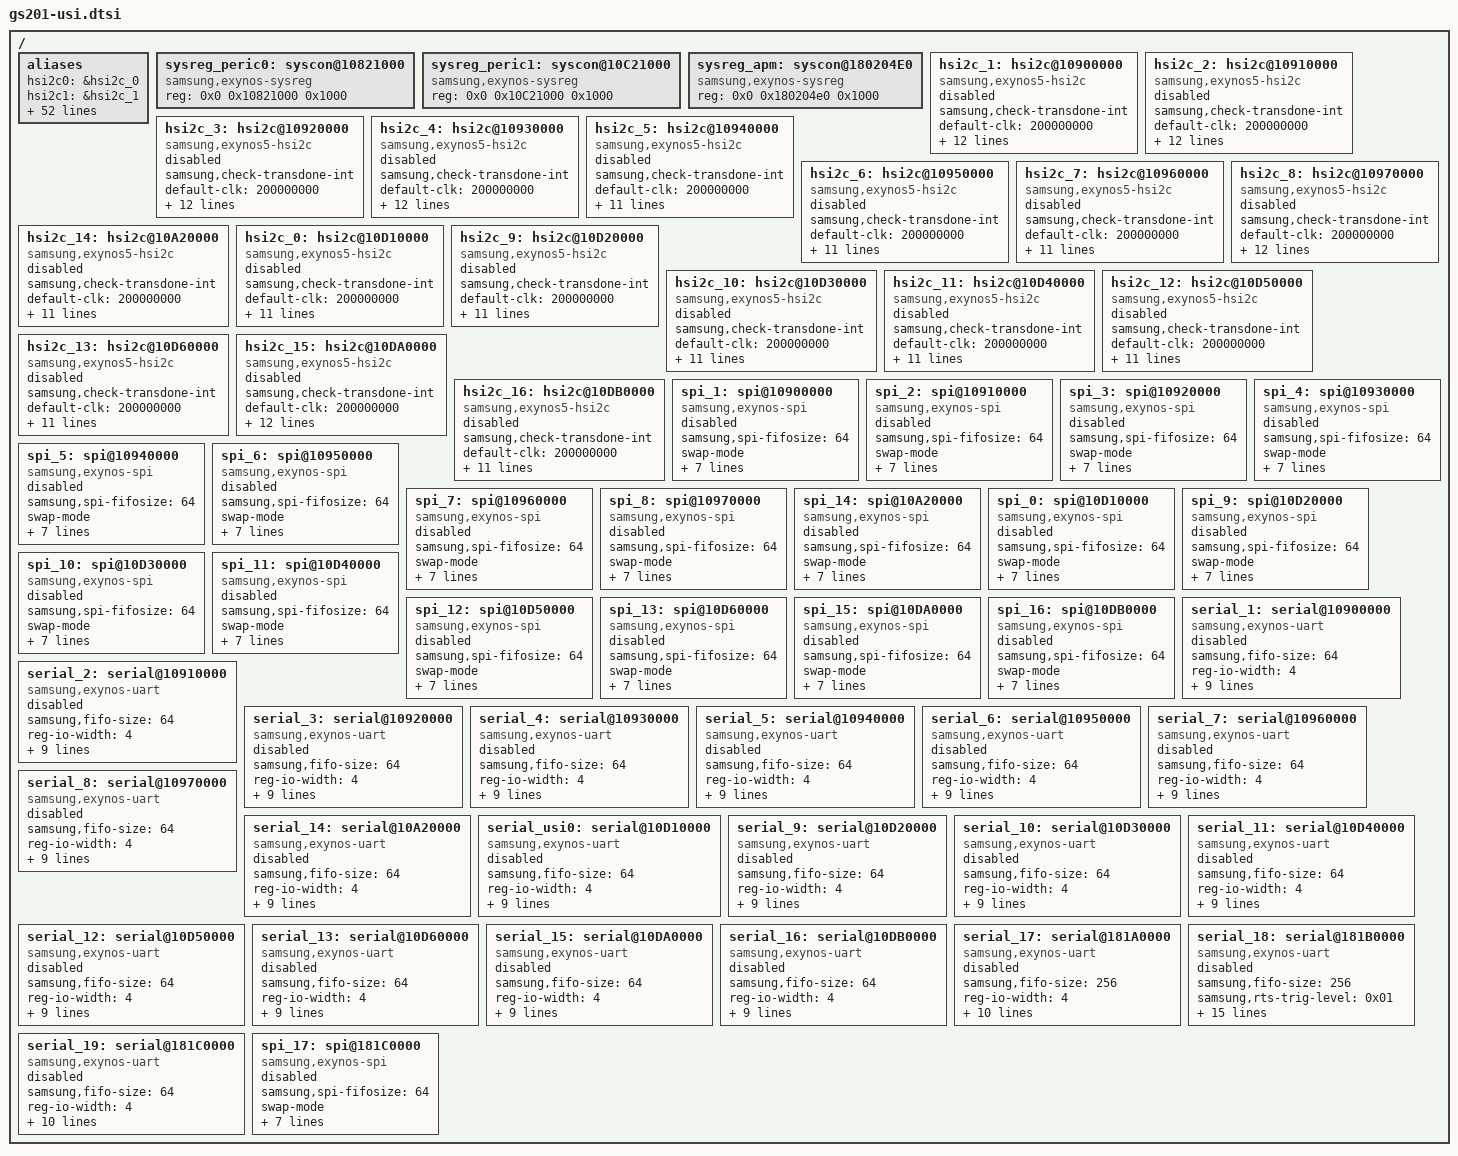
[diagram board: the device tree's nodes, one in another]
// SPDX-License-Identifier: GPL-2.0-only
/*
 * Copyright 2020 Google LLC.
 *
 */

/ {
	aliases {
		hsi2c0 = &hsi2c_0;
		hsi2c1 = &hsi2c_1;
		hsi2c2 = &hsi2c_2;
		hsi2c3 = &hsi2c_3;
		hsi2c4 = &hsi2c_4;
		hsi2c5 = &hsi2c_5;
		hsi2c6 = &hsi2c_6;
		hsi2c7 = &hsi2c_7;
		hsi2c8 = &hsi2c_8;
		hsi2c9 = &hsi2c_9;
		hsi2c10 = &hsi2c_10;
		hsi2c11 = &hsi2c_11;
		hsi2c12 = &hsi2c_12;
		hsi2c13 = &hsi2c_13;
		hsi2c14 = &hsi2c_14;
		hsi2c15 = &hsi2c_15;
		hsi2c16 = &hsi2c_16;
		spi0 = &spi_0;
		spi1 = &spi_1;
		spi2 = &spi_2;
		spi3 = &spi_3;
		spi4 = &spi_4;
		spi5 = &spi_5;
		spi6 = &spi_6;
		spi7 = &spi_7;
		spi8 = &spi_8;
		spi9 = &spi_9;
		spi10 = &spi_10;
		spi11 = &spi_11;
		spi12 = &spi_12;
		spi13 = &spi_13;
		spi14 = &spi_14;
		spi15 = &spi_15;
		spi16 = &spi_16;
		spi17 = &spi_17;
		uart1 = &serial_1;
		uart2 = &serial_2;
		uart3 = &serial_3;
		uart4 = &serial_4;
		uart5 = &serial_5;
		uart6 = &serial_6;
		uart7 = &serial_7;
		uart8 = &serial_8;
		uart9 = &serial_9;
		uart10 = &serial_10;
		uart11 = &serial_11;
		uart12 = &serial_12;
		uart13 = &serial_13;
		uart14 = &serial_14;
		uart15 = &serial_15;
		uart16 = &serial_16;
		uart17 = &serial_17;
		uart18 = &serial_18;
		uart19 = &serial_19;
	};

	sysreg_peric0: syscon@10821000 {
		compatible = "samsung,exynos-sysreg", "syscon";
		reg = <0x0 0x10821000 0x1000>;
	};

	sysreg_peric1: syscon@10C21000 {
		compatible = "samsung,exynos-sysreg", "syscon";
		reg = <0x0 0x10C21000 0x1000>;
	};

	sysreg_apm: syscon@180204E0 {
		compatible = "samsung,exynos-sysreg", "syscon";
		reg = <0x0 0x180204e0 0x1000>;
	};

	hsi2c_1: hsi2c@10900000 {
		compatible = "samsung,exynos5-hsi2c";
		samsung,check-transdone-int;
		#address-cells = <0x00000001>;
		#size-cells = <0x00000000>;
		default-clk = <200000000>;
		samsung,scl-clk-stretching;
		samsung,no_lose_arbitration;
		samsung,usi-i2c-v2;
		interrupts = <GIC_SPI IRQ_USI1_USI_PERIC0 ITLH>;
		samsung,usi-phandle = <&sysreg_peric0>;
		pinctrl-names = "default";
		pinctrl-0 = <&hsi2c1_bus>;
		clocks = <&clock VDOUT_CLK_PERIC0_USI1_USI>, <&clock GATE_PERIC0_TOP0_USI1_USI>;
		clock-names = "ipclk_hsi2c", "gate_hsi2c_clk";
		gpio_scl= <&gpp2 0 0x1>;
		gpio_sda= <&gpp2 1 0x1>;
		samsung,usi-offset = <0x00000000>;
		reg = <0x00000000 0x10900000 0x00001000>;
		status = "disabled";
	};
	hsi2c_2: hsi2c@10910000 {
		compatible = "samsung,exynos5-hsi2c";
		samsung,check-transdone-int;
		#address-cells = <0x00000001>;
		#size-cells = <0x00000000>;
		default-clk = <200000000>;
		samsung,scl-clk-stretching;
		samsung,no_lose_arbitration;
		samsung,usi-i2c-v2;
		interrupts = <GIC_SPI IRQ_USI2_USI_PERIC0 ITLH>;
		pinctrl-names = "default";
		pinctrl-0 = <&hsi2c2_bus>;
		clocks = <&clock VDOUT_CLK_PERIC0_USI2_USI>, <&clock GATE_PERIC0_TOP0_USI2_USI>;
		clock-names = "ipclk_hsi2c", "gate_hsi2c_clk";
		gpio_scl= <&gpp4 0 0x1>;
		gpio_sda= <&gpp4 1 0x1>;
		samsung,usi-phandle = <&sysreg_peric0>;
		samsung,usi-offset = <0x00000004>;
		reg = <0x00000000 0x10910000 0x00001000>;
		status = "disabled";
	};
	hsi2c_3: hsi2c@10920000 {
		compatible = "samsung,exynos5-hsi2c";
		samsung,check-transdone-int;
		#address-cells = <0x00000001>;
		#size-cells = <0x00000000>;
		default-clk = <200000000>;
		samsung,scl-clk-stretching;
		samsung,no_lose_arbitration;
		samsung,usi-i2c-v2;
		interrupts = <GIC_SPI IRQ_USI3_USI_PERIC0 ITLH>;
		pinctrl-names = "default";
		pinctrl-0 = <&hsi2c3_bus>;
		clocks = <&clock VDOUT_CLK_PERIC0_USI3_USI>, <&clock GATE_PERIC0_TOP0_USI3_USI>;
		clock-names = "ipclk_hsi2c", "gate_hsi2c_clk";
		gpio_scl= <&gpp6 0 0x1>;
		gpio_sda= <&gpp6 1 0x1>;
		samsung,usi-phandle = <&sysreg_peric0>;
		samsung,usi-offset = <0x00000008>;
		reg = <0x00000000 0x10920000 0x00001000>;
		status = "disabled";
	};
	hsi2c_4: hsi2c@10930000 {
		compatible = "samsung,exynos5-hsi2c";
		samsung,check-transdone-int;
		#address-cells = <0x00000001>;
		#size-cells = <0x00000000>;
		default-clk = <200000000>;
		samsung,scl-clk-stretching;
		samsung,no_lose_arbitration;
		samsung,usi-i2c-v2;
		interrupts = <GIC_SPI IRQ_USI4_USI_PERIC0 ITLH>;
		pinctrl-names = "default";
		pinctrl-0 = <&hsi2c4_bus>;
		clocks = <&clock VDOUT_CLK_PERIC0_USI4_USI>, <&clock GATE_PERIC0_TOP0_USI4_USI>;
		clock-names = "ipclk_hsi2c", "gate_hsi2c_clk";
		gpio_scl= <&gpp8 0 0x1>;
		gpio_sda= <&gpp8 1 0x1>;
		samsung,usi-phandle = <&sysreg_peric0>;
		samsung,usi-offset = <0x0000000c>;
		reg = <0x00000000 0x10930000 0x00001000>;
		status = "disabled";
	};
	hsi2c_5: hsi2c@10940000 {
		compatible = "samsung,exynos5-hsi2c";
		samsung,check-transdone-int;
		#address-cells = <0x00000001>;
		#size-cells = <0x00000000>;
		default-clk = <200000000>;
		samsung,scl-clk-stretching;
		samsung,usi-i2c-v2;
		interrupts = <GIC_SPI IRQ_USI5_USI_PERIC0 ITLH>;
		pinctrl-names = "default";
		pinctrl-0 = <&hsi2c5_bus>;
		clocks = <&clock VDOUT_CLK_PERIC0_USI5_USI>, <&clock GATE_PERIC0_TOP0_USI5_USI>;
		clock-names = "ipclk_hsi2c", "gate_hsi2c_clk";
		gpio_scl= <&gpp10 0 0x1>;
		gpio_sda= <&gpp10 1 0x1>;
		samsung,usi-phandle = <&sysreg_peric0>;
		samsung,usi-offset = <0x00000010>;
		reg = <0x00000000 0x10940000 0x00001000>;
		status = "disabled";
	};
	hsi2c_6: hsi2c@10950000 {
		compatible = "samsung,exynos5-hsi2c";
		samsung,check-transdone-int;
		#address-cells = <0x00000001>;
		#size-cells = <0x00000000>;
		default-clk = <200000000>;
		samsung,scl-clk-stretching;
		samsung,usi-i2c-v2;
		interrupts = <GIC_SPI IRQ_USI6_USI_PERIC0 ITLH>;
		pinctrl-names = "default";
		pinctrl-0 = <&hsi2c6_bus>;
		clocks = <&clock VDOUT_CLK_PERIC0_USI6_USI>, <&clock GATE_PERIC0_TOP0_USI6_USI>;
		clock-names = "ipclk_hsi2c", "gate_hsi2c_clk";
		gpio_scl= <&gpp12 0 0x1>;
		gpio_sda= <&gpp12 1 0x1>;
		samsung,usi-phandle = <&sysreg_peric0>;
		samsung,usi-offset = <0x00000014>;
		reg = <0x00000000 0x10950000 0x00001000>;
		status = "disabled";
	};
	hsi2c_7: hsi2c@10960000 {
		compatible = "samsung,exynos5-hsi2c";
		samsung,check-transdone-int;
		#address-cells = <0x00000001>;
		#size-cells = <0x00000000>;
		default-clk = <200000000>;
		samsung,scl-clk-stretching;
		samsung,usi-i2c-v2;
		interrupts = <GIC_SPI IRQ_USI7_USI_PERIC0 ITLH>;
		pinctrl-names = "default";
		pinctrl-0 = <&hsi2c7_bus>;
		clocks = <&clock VDOUT_CLK_PERIC0_USI7_USI>, <&clock GATE_PERIC0_TOP0_USI7_USI>;
		clock-names = "ipclk_hsi2c", "gate_hsi2c_clk";
		gpio_scl= <&gpp14 0 0x1>;
		gpio_sda= <&gpp14 1 0x1>;
		samsung,usi-phandle = <&sysreg_peric0>;
		samsung,usi-offset = <0x00000018>;
		reg = <0x00000000 0x10960000 0x00001000>;
		status = "disabled";
	};
	hsi2c_8: hsi2c@10970000 {
		compatible = "samsung,exynos5-hsi2c";
		samsung,check-transdone-int;
		#address-cells = <0x00000001>;
		#size-cells = <0x00000000>;
		default-clk = <200000000>;
		samsung,scl-clk-stretching;
		samsung,no_lose_arbitration;
		samsung,usi-i2c-v2;
		interrupts = <GIC_SPI IRQ_USI8_USI_PERIC0 ITLH>;
		pinctrl-names = "default";
		pinctrl-0 = <&hsi2c8_bus>;
		clocks = <&clock VDOUT_CLK_PERIC0_USI8_USI>, <&clock GATE_PERIC0_TOP0_USI8_USI>;
		clock-names = "ipclk_hsi2c", "gate_hsi2c_clk";
		gpio_scl= <&gpp16 0 0x1>;
		gpio_sda= <&gpp16 1 0x1>;
		samsung,usi-phandle = <&sysreg_peric0>;
		samsung,usi-offset = <0x0000001c>;
		reg = <0x00000000 0x10970000 0x00001000>;
		status = "disabled";
	};
	hsi2c_14: hsi2c@10A20000 {
		compatible = "samsung,exynos5-hsi2c";
		samsung,check-transdone-int;
		#address-cells = <0x00000001>;
		#size-cells = <0x00000000>;
		default-clk = <200000000>;
		samsung,scl-clk-stretching;
		samsung,usi-i2c-v2;
		interrupts = <GIC_SPI IRQ_USI14_USI_PERIC0 ITLH>;
		pinctrl-names = "default";
		pinctrl-0 = <&hsi2c14_bus>;
		clocks = <&clock VDOUT_CLK_PERIC0_USI14_USI>, <&clock GATE_PERIC0_TOP1_USI14_USI>;
		clock-names = "ipclk_hsi2c", "gate_hsi2c_clk";
		gpio_scl= <&gpp18 0 0x1>;
		gpio_sda= <&gpp18 1 0x1>;
		samsung,usi-phandle = <&sysreg_peric0>;
		samsung,usi-offset = <0x00000028>;
		reg = <0x00000000 0x10a20000 0x00001000>;
		status = "disabled";
	};
	hsi2c_0: hsi2c@10D10000 {
		compatible = "samsung,exynos5-hsi2c";
		samsung,check-transdone-int;
		#address-cells = <0x00000001>;
		#size-cells = <0x00000000>;
		default-clk = <200000000>;
		samsung,scl-clk-stretching;
		samsung,usi-i2c-v2;
		interrupts = <GIC_SPI IRQ_USI0_USI_PERIC1 ITLH>;
		pinctrl-names = "default";
		pinctrl-0 = <&hsi2c0_bus>;
		clocks = <&clock VDOUT_CLK_PERIC1_USI0_USI>, <&clock GATE_PERIC1_TOP0_USI0_USI>;
		clock-names = "ipclk_hsi2c", "gate_hsi2c_clk";
		gpio_scl= <&gpp20 0 0x1>;
		gpio_sda= <&gpp20 1 0x1>;
		samsung,usi-phandle = <&sysreg_peric1>;
		samsung,usi-offset = <0x00000000>;
		reg = <0x00000000 0x10d10000 0x00001000>;
		status = "disabled";
	};
	hsi2c_9: hsi2c@10D20000 {
		compatible = "samsung,exynos5-hsi2c";
		samsung,check-transdone-int;
		#address-cells = <0x00000001>;
		#size-cells = <0x00000000>;
		default-clk = <200000000>;
		samsung,scl-clk-stretching;
		samsung,usi-i2c-v2;
		interrupts = <GIC_SPI IRQ_USI9_USI_PERIC1 ITLH>;
		pinctrl-names = "default";
		pinctrl-0 = <&hsi2c9_bus>;
		clocks = <&clock VDOUT_CLK_PERIC1_USI9_USI>, <&clock GATE_PERIC1_TOP0_USI9_USI>;
		clock-names = "ipclk_hsi2c", "gate_hsi2c_clk";
		gpio_scl= <&gpp20 4 0x1>;
		gpio_sda= <&gpp20 5 0x1>;
		samsung,usi-phandle = <&sysreg_peric1>;
		samsung,usi-offset = <0x00000004>;
		reg = <0x00000000 0x10d20000 0x00001000>;
		status = "disabled";
	};
	hsi2c_10: hsi2c@10D30000 {
		compatible = "samsung,exynos5-hsi2c";
		samsung,check-transdone-int;
		#address-cells = <0x00000001>;
		#size-cells = <0x00000000>;
		default-clk = <200000000>;
		samsung,scl-clk-stretching;
		samsung,usi-i2c-v2;
		interrupts = <GIC_SPI IRQ_USI10_USI_PERIC1 ITLH>;
		pinctrl-names = "default";
		pinctrl-0 = <&hsi2c10_bus>;
		clocks = <&clock VDOUT_CLK_PERIC1_USI10_USI>, <&clock GATE_PERIC1_TOP0_USI10_USI>;
		clock-names = "ipclk_hsi2c", "gate_hsi2c_clk";
		gpio_scl= <&gpp21 0 0x1>;
		gpio_sda= <&gpp21 1 0x1>;
		samsung,usi-phandle = <&sysreg_peric1>;
		samsung,usi-offset = <0x00000008>;
		reg = <0x00000000 0x10d30000 0x00001000>;
		status = "disabled";
	};
	hsi2c_11: hsi2c@10D40000 {
		compatible = "samsung,exynos5-hsi2c";
		samsung,check-transdone-int;
		#address-cells = <0x00000001>;
		#size-cells = <0x00000000>;
		default-clk = <200000000>;
		samsung,scl-clk-stretching;
		samsung,usi-i2c-v2;
		interrupts = <GIC_SPI IRQ_USI11_USI_PERIC1 ITLH>;
		pinctrl-names = "default";
		pinctrl-0 = <&hsi2c11_bus>;
		clocks = <&clock VDOUT_CLK_PERIC1_USI11_USI>, <&clock GATE_PERIC1_TOP0_USI11_USI>;
		clock-names = "ipclk_hsi2c", "gate_hsi2c_clk";
		gpio_scl= <&gpp23 0 0x1>;
		gpio_sda= <&gpp23 1 0x1>;
		samsung,usi-phandle = <&sysreg_peric1>;
		samsung,usi-offset = <0x0000000c>;
		reg = <0x00000000 0x10d40000 0x00001000>;
		status = "disabled";
	};
	hsi2c_12: hsi2c@10D50000 {
		compatible = "samsung,exynos5-hsi2c";
		samsung,check-transdone-int;
		#address-cells = <0x00000001>;
		#size-cells = <0x00000000>;
		default-clk = <200000000>;
		samsung,scl-clk-stretching;
		samsung,usi-i2c-v2;
		interrupts = <GIC_SPI IRQ_USI12_USI_PERIC1 ITLH>;
		pinctrl-names = "default";
		pinctrl-0 = <&hsi2c12_bus>;
		clocks = <&clock VDOUT_CLK_PERIC1_USI12_USI>, <&clock GATE_PERIC1_TOP0_USI12_USI>;
		clock-names = "ipclk_hsi2c", "gate_hsi2c_clk";
		gpio_scl= <&gpp23 4 0x1>;
		gpio_sda= <&gpp23 5 0x1>;
		samsung,usi-phandle = <&sysreg_peric1>;
		samsung,usi-offset = <0x00000010>;
		reg = <0x00000000 0x10d50000 0x00001000>;
		status = "disabled";
	};
	hsi2c_13: hsi2c@10D60000 {
		compatible = "samsung,exynos5-hsi2c";
		samsung,check-transdone-int;
		#address-cells = <0x00000001>;
		#size-cells = <0x00000000>;
		default-clk = <200000000>;
		samsung,scl-clk-stretching;
		samsung,usi-i2c-v2;
		interrupts = <GIC_SPI IRQ_USI13_USI_PERIC1 ITLH>;
		pinctrl-names = "default";
		pinctrl-0 = <&hsi2c13_bus>;
		clocks = <&clock VDOUT_CLK_PERIC1_USI13_USI>, <&clock GATE_PERIC1_TOP0_USI13_USI>;
		clock-names = "ipclk_hsi2c", "gate_hsi2c_clk";
		gpio_scl= <&gpp25 0 0x1>;
		gpio_sda= <&gpp25 1 0x1>;
		samsung,usi-phandle = <&sysreg_peric1>;
		samsung,usi-offset = <0x00000014>;
		reg = <0x00000000 0x10d60000 0x00001000>;
		status = "disabled";
	};
	hsi2c_15: hsi2c@10DA0000 {
		compatible = "samsung,exynos5-hsi2c";
		samsung,check-transdone-int;
		#address-cells = <0x00000001>;
		#size-cells = <0x00000000>;
		default-clk = <200000000>;
		samsung,scl-clk-stretching;
		samsung,no_lose_arbitration;
		samsung,usi-i2c-v2;
		interrupts = <GIC_SPI IRQ_USI15_USI_PERIC1 ITLH>;
		pinctrl-names = "default";
		pinctrl-0 = <&hsi2c15_bus>;
		clocks = <&clock VDOUT_CLK_PERIC1_USI15_USI>, <&clock GATE_PERIC1_TOP0_USI15_USI>;
		clock-names = "ipclk_hsi2c", "gate_hsi2c_clk";
		gpio_scl= <&gpp24 0 0x1>;
		gpio_sda= <&gpp24 1 0x1>;
		samsung,usi-phandle = <&sysreg_peric1>;
		samsung,usi-offset = <0x00000018>;
		reg = <0x00000000 0x10da0000 0x00001000>;
		status = "disabled";
	};
	hsi2c_16: hsi2c@10DB0000 {
		compatible = "samsung,exynos5-hsi2c";
		samsung,check-transdone-int;
		#address-cells = <0x00000001>;
		#size-cells = <0x00000000>;
		default-clk = <200000000>;
		samsung,scl-clk-stretching;
		samsung,usi-i2c-v2;
		interrupts = <GIC_SPI IRQ_USI16_USI_PERIC1 ITLH>;
		pinctrl-names = "default";
		pinctrl-0 = <&hsi2c16_bus>;
		clocks = <&clock VDOUT_CLK_PERIC1_USI16_USI>, <&clock GATE_PERIC1_TOP0_USI16_USI>;
		clock-names = "ipclk_hsi2c", "gate_hsi2c_clk";
		gpio_scl= <&gpp26 0 0x1>;
		gpio_sda= <&gpp26 1 0x1>;
		samsung,usi-phandle = <&sysreg_peric1>;
		samsung,usi-offset = <0x0000001c>;
		reg = <0x00000000 0x10db0000 0x00001000>;
		status = "disabled";
	};
	spi_1: spi@10900000 {
		compatible = "samsung,exynos-spi";
		samsung,spi-fifosize = <64>;
		swap-mode;
		#address-cells = <0x00000001>;
		#size-cells = <0x00000000>;
//		dma-mode;
//		dmas = <&pdma0 2 &pdma0 3>;
		dma-names = "tx", "rx";
		clocks = <&clock VDOUT_CLK_PERIC0_USI1_USI>, <&clock GATE_PERIC0_TOP0_USI1_USI>;
		clock-names = "ipclk_spi", "gate_spi_clk";
		pinctrl-names = "default";
		pinctrl-0 = <&spi1_bus>;
		interrupts = <GIC_SPI IRQ_USI1_USI_PERIC0 ITLH>;
		samsung,usi-phandle = <&sysreg_peric0>;
		samsung,usi-offset = <0x00000000>;
		reg = <0x00000000 0x10900000 0x00001000>;
		status = "disabled";
	};
	spi_2: spi@10910000 {
		compatible = "samsung,exynos-spi";
		samsung,spi-fifosize = <64>;
		swap-mode;
		#address-cells = <0x00000001>;
		#size-cells = <0x00000000>;
//		dma-mode;
//		dmas = <&pdma0 4 &pdma0 5>;
		dma-names = "tx", "rx";
		clocks = <&clock VDOUT_CLK_PERIC0_USI2_USI>, <&clock GATE_PERIC0_TOP0_USI2_USI>;
		clock-names = "ipclk_spi", "gate_spi_clk";
		pinctrl-names = "default";
		pinctrl-0 = <&spi2_bus>;
		interrupts = <GIC_SPI IRQ_USI2_USI_PERIC0 ITLH>;
		samsung,usi-phandle = <&sysreg_peric0>;
		samsung,usi-offset = <0x00000004>;
		reg = <0x00000000 0x10910000 0x00001000>;
		status = "disabled";
	};
	spi_3: spi@10920000 {
		compatible = "samsung,exynos-spi";
		samsung,spi-fifosize = <64>;
		swap-mode;
		#address-cells = <0x00000001>;
		#size-cells = <0x00000000>;
//		dma-mode;
//		dmas = <&pdma0 6 &pdma0 7>;
		dma-names = "tx", "rx";
		clocks = <&clock VDOUT_CLK_PERIC0_USI3_USI>, <&clock GATE_PERIC0_TOP0_USI3_USI>;
		clock-names = "ipclk_spi", "gate_spi_clk";
		pinctrl-names = "default";
		pinctrl-0 = <&spi3_bus>;
		interrupts = <GIC_SPI IRQ_USI3_USI_PERIC0 ITLH>;
		samsung,usi-phandle = <&sysreg_peric0>;
		samsung,usi-offset = <0x00000008>;
		reg = <0x00000000 0x10920000 0x00001000>;
		status = "disabled";
	};
	spi_4: spi@10930000 {
		compatible = "samsung,exynos-spi";
		samsung,spi-fifosize = <64>;
		swap-mode;
		#address-cells = <0x00000001>;
		#size-cells = <0x00000000>;
//		dma-mode;
//		dmas = <&pdma0 8 &pdma0 9>;
		dma-names = "tx", "rx";
		clocks = <&clock VDOUT_CLK_PERIC0_USI4_USI>, <&clock GATE_PERIC0_TOP0_USI4_USI>;
		clock-names = "ipclk_spi", "gate_spi_clk";
		pinctrl-names = "default";
		pinctrl-0 = <&spi4_bus>;
		interrupts = <GIC_SPI IRQ_USI4_USI_PERIC0 ITLH>;
		samsung,usi-phandle = <&sysreg_peric0>;
		samsung,usi-offset = <0x0000000c>;
		reg = <0x00000000 0x10930000 0x00001000>;
		status = "disabled";
	};
	spi_5: spi@10940000 {
		compatible = "samsung,exynos-spi";
		samsung,spi-fifosize = <64>;
		swap-mode;
		#address-cells = <0x00000001>;
		#size-cells = <0x00000000>;
//		dma-mode;
//		dmas = <&pdma0 10 &pdma0 11>;
		dma-names = "tx", "rx";
		clocks = <&clock VDOUT_CLK_PERIC0_USI5_USI>, <&clock GATE_PERIC0_TOP0_USI5_USI>;
		clock-names = "ipclk_spi", "gate_spi_clk";
		pinctrl-names = "default";
		pinctrl-0 = <&spi5_bus>;
		interrupts = <GIC_SPI IRQ_USI5_USI_PERIC0 ITLH>;
		samsung,usi-phandle = <&sysreg_peric0>;
		samsung,usi-offset = <0x00000010>;
		reg = <0x00000000 0x10940000 0x00001000>;
		status = "disabled";
	};
	spi_6: spi@10950000 {
		compatible = "samsung,exynos-spi";
		samsung,spi-fifosize = <64>;
		swap-mode;
		#address-cells = <0x00000001>;
		#size-cells = <0x00000000>;
//		dma-mode;
//		dmas = <&pdma0 12 &pdma0 13>;
		dma-names = "tx", "rx";
		clocks = <&clock VDOUT_CLK_PERIC0_USI6_USI>, <&clock GATE_PERIC0_TOP0_USI6_USI>;
		clock-names = "ipclk_spi", "gate_spi_clk";
		pinctrl-names = "default";
		pinctrl-0 = <&spi6_bus>;
		interrupts = <GIC_SPI IRQ_USI6_USI_PERIC0 ITLH>;
		samsung,usi-phandle = <&sysreg_peric0>;
		samsung,usi-offset = <0x00000014>;
		reg = <0x00000000 0x10950000 0x00001000>;
		status = "disabled";
	};
	spi_7: spi@10960000 {
		compatible = "samsung,exynos-spi";
		samsung,spi-fifosize = <64>;
		swap-mode;
		#address-cells = <0x00000001>;
		#size-cells = <0x00000000>;
//		dma-mode;
//		dmas = <&pdma0 14 &pdma0 15>;
		dma-names = "tx", "rx";
		clocks = <&clock VDOUT_CLK_PERIC0_USI7_USI>, <&clock GATE_PERIC0_TOP0_USI7_USI>;
		clock-names = "ipclk_spi", "gate_spi_clk";
		pinctrl-names = "default";
		pinctrl-0 = <&spi7_bus>;
		interrupts = <GIC_SPI IRQ_USI7_USI_PERIC0 ITLH>;
		samsung,usi-phandle = <&sysreg_peric0>;
		samsung,usi-offset = <0x00000018>;
		reg = <0x00000000 0x10960000 0x00001000>;
		status = "disabled";
	};
	spi_8: spi@10970000 {
		compatible = "samsung,exynos-spi";
		samsung,spi-fifosize = <64>;
		swap-mode;
		#address-cells = <0x00000001>;
		#size-cells = <0x00000000>;
//		dma-mode;
//		dmas = <&pdma0 16 &pdma0 17>;
		dma-names = "tx", "rx";
		clocks = <&clock VDOUT_CLK_PERIC0_USI8_USI>, <&clock GATE_PERIC0_TOP0_USI8_USI>;
		clock-names = "ipclk_spi", "gate_spi_clk";
		pinctrl-names = "default";
		pinctrl-0 = <&spi8_bus>;
		interrupts = <GIC_SPI IRQ_USI8_USI_PERIC0 ITLH>;
		samsung,usi-phandle = <&sysreg_peric0>;
		samsung,usi-offset = <0x0000001c>;
		reg = <0x00000000 0x10970000 0x00001000>;
		status = "disabled";
	};
	spi_14: spi@10A20000 {
		compatible = "samsung,exynos-spi";
		samsung,spi-fifosize = <64>;
		swap-mode;
		#address-cells = <0x00000001>;
		#size-cells = <0x00000000>;
//		dma-mode;
//		dmas = <&pdma0 28 &pdma0 29>;
		dma-names = "tx", "rx";
		clocks = <&clock VDOUT_CLK_PERIC0_USI14_USI>, <&clock GATE_PERIC0_TOP1_USI14_USI>;
		clock-names = "ipclk_spi", "gate_spi_clk";
		pinctrl-names = "default";
		pinctrl-0 = <&spi14_bus>;
		interrupts = <GIC_SPI IRQ_USI14_USI_PERIC0 ITLH>;
		samsung,usi-phandle = <&sysreg_peric0>;
		samsung,usi-offset = <0x00000028>;
		reg = <0x00000000 0x10a20000 0x00001000>;
		status = "disabled";
	};
	spi_0: spi@10D10000 {
		compatible = "samsung,exynos-spi";
		samsung,spi-fifosize = <64>;
		swap-mode;
		#address-cells = <0x00000001>;
		#size-cells = <0x00000000>;
//		dma-mode;
//		dmas = <&pdma0 0 &pdma0 1>;
		dma-names = "tx", "rx";
		clocks = <&clock VDOUT_CLK_PERIC1_USI0_USI>, <&clock GATE_PERIC1_TOP0_USI0_USI>;
		clock-names = "ipclk_spi", "gate_spi_clk";
		pinctrl-names = "default";
		pinctrl-0 = <&spi0_bus>;
		interrupts = <GIC_SPI IRQ_USI0_USI_PERIC1 ITLH>;
		samsung,usi-phandle = <&sysreg_peric1>;
		samsung,usi-offset = <0x00000000>;
		reg = <0x00000000 0x10d10000 0x00001000>;
		status = "disabled";
	};
	spi_9: spi@10D20000 {
		compatible = "samsung,exynos-spi";
		samsung,spi-fifosize = <64>;
		swap-mode;
		#address-cells = <0x00000001>;
		#size-cells = <0x00000000>;
//		dma-mode;
//		dmas = <&pdma0 18 &pdma0 19>;
		dma-names = "tx", "rx";
		clocks = <&clock VDOUT_CLK_PERIC1_USI9_USI>, <&clock GATE_PERIC1_TOP0_USI9_USI>;
		clock-names = "ipclk_spi", "gate_spi_clk";
		pinctrl-names = "default";
		pinctrl-0 = <&spi9_bus>;
		interrupts = <GIC_SPI IRQ_USI9_USI_PERIC1 ITLH>;
		samsung,usi-phandle = <&sysreg_peric1>;
		samsung,usi-offset = <0x00000004>;
		reg = <0x00000000 0x10d20000 0x00001000>;
		status = "disabled";
	};
	spi_10: spi@10D30000 {
		compatible = "samsung,exynos-spi";
		samsung,spi-fifosize = <64>;
		swap-mode;
		#address-cells = <0x00000001>;
		#size-cells = <0x00000000>;
//		dma-mode;
//		dmas = <&pdma0 20 &pdma0 21>;
		dma-names = "tx", "rx";
		clocks = <&clock VDOUT_CLK_PERIC1_USI10_USI>, <&clock GATE_PERIC1_TOP0_USI10_USI>;
		clock-names = "ipclk_spi", "gate_spi_clk";
		pinctrl-names = "default";
		pinctrl-0 = <&spi10_bus>;
		interrupts = <GIC_SPI IRQ_USI10_USI_PERIC1 ITLH>;
		samsung,usi-phandle = <&sysreg_peric1>;
		samsung,usi-offset = <0x00000008>;
		reg = <0x00000000 0x10d30000 0x00001000>;
		status = "disabled";
	};
	spi_11: spi@10D40000 {
		compatible = "samsung,exynos-spi";
		samsung,spi-fifosize = <64>;
		swap-mode;
		#address-cells = <0x00000001>;
		#size-cells = <0x00000000>;
//		dma-mode;
//		dmas = <&pdma0 22 &pdma0 23>;
		dma-names = "tx", "rx";
		clocks = <&clock VDOUT_CLK_PERIC1_USI11_USI>, <&clock GATE_PERIC1_TOP0_USI11_USI>;
		clock-names = "ipclk_spi", "gate_spi_clk";
		pinctrl-names = "default";
		pinctrl-0 = <&spi11_bus>;
		interrupts = <GIC_SPI IRQ_USI11_USI_PERIC1 ITLH>;
		samsung,usi-phandle = <&sysreg_peric1>;
		samsung,usi-offset = <0x0000000c>;
		reg = <0x00000000 0x10d40000 0x00001000>;
		status = "disabled";
	};
	spi_12: spi@10D50000 {
		compatible = "samsung,exynos-spi";
		samsung,spi-fifosize = <64>;
		swap-mode;
		#address-cells = <0x00000001>;
		#size-cells = <0x00000000>;
//		dma-mode;
//		dmas = <&pdma0 24 &pdma0 25>;
		dma-names = "tx", "rx";
		clocks = <&clock VDOUT_CLK_PERIC1_USI12_USI>, <&clock GATE_PERIC1_TOP0_USI12_USI>;
		clock-names = "ipclk_spi", "gate_spi_clk";
		pinctrl-names = "default";
		pinctrl-0 = <&spi12_bus>;
		interrupts = <GIC_SPI IRQ_USI12_USI_PERIC1 ITLH>;
		samsung,usi-phandle = <&sysreg_peric1>;
		samsung,usi-offset = <0x00000010>;
		reg = <0x00000000 0x10d50000 0x00001000>;
		status = "disabled";
	};
	spi_13: spi@10D60000 {
		compatible = "samsung,exynos-spi";
		samsung,spi-fifosize = <64>;
		swap-mode;
		#address-cells = <0x00000001>;
		#size-cells = <0x00000000>;
//		dma-mode;
//		dmas = <&pdma1 0 &pdma1 1>;
		dma-names = "tx", "rx";
		clocks = <&clock VDOUT_CLK_PERIC1_USI13_USI>, <&clock GATE_PERIC1_TOP0_USI13_USI>;
		clock-names = "ipclk_spi", "gate_spi_clk";
		pinctrl-names = "default";
		pinctrl-0 = <&spi13_bus>;
		interrupts = <GIC_SPI IRQ_USI13_USI_PERIC1 ITLH>;
		samsung,usi-phandle = <&sysreg_peric1>;
		samsung,usi-offset = <0x00000014>;
		reg = <0x00000000 0x10d60000 0x00001000>;
		status = "disabled";
	};
	spi_15: spi@10DA0000 {
		compatible = "samsung,exynos-spi";
		samsung,spi-fifosize = <64>;
		swap-mode;
		#address-cells = <0x00000001>;
		#size-cells = <0x00000000>;
//		dma-mode;
//		dmas = <&pdma1 2 &pdma1 3>;
		dma-names = "tx", "rx";
		clocks = <&clock VDOUT_CLK_PERIC1_USI15_USI>, <&clock GATE_PERIC1_TOP0_USI15_USI>;
		clock-names = "ipclk_spi", "gate_spi_clk";
		pinctrl-names = "default";
		pinctrl-0 = <&spi15_bus>;
		interrupts = <GIC_SPI IRQ_USI15_USI_PERIC1 ITLH>;
		samsung,usi-phandle = <&sysreg_peric1>;
		samsung,usi-offset = <0x00000018>;
		reg = <0x00000000 0x10da0000 0x00001000>;
		status = "disabled";
	};
	spi_16: spi@10DB0000 {
		compatible = "samsung,exynos-spi";
		samsung,spi-fifosize = <64>;
		swap-mode;
		#address-cells = <0x00000001>;
		#size-cells = <0x00000000>;
//		dma-mode;
//		dmas = <&pdma0 26 &pdma0 27>;
		dma-names = "tx", "rx";
		clocks = <&clock VDOUT_CLK_PERIC1_USI16_USI>, <&clock GATE_PERIC1_TOP0_USI16_USI>;
		clock-names = "ipclk_spi", "gate_spi_clk";
		pinctrl-names = "default";
		pinctrl-0 = <&spi16_bus>;
		interrupts = <GIC_SPI IRQ_USI16_USI_PERIC1 ITLH>;
		samsung,usi-phandle = <&sysreg_peric1>;
		samsung,usi-offset = <0x0000001c>;
		reg = <0x00000000 0x10db0000 0x00001000>;
		status = "disabled";
	};
	/* BLK_PERIC0 USI1_USI */
	serial_1: serial@10900000 {
		compatible = "samsung,exynos-uart";
		samsung,fifo-size = <64>;
		reg-io-width = <4>;
		samsung,separate-uart-clk;
		samsung,usi-serial-v2;
		#address-cells = <0x00000001>;
		#size-cells = <0x00000000>;
		pinctrl-names = "default";
		pinctrl-0 = <&uart1_bus_single>; /* or _bus_dual */
		clocks = <&clock GATE_PERIC0_TOP0_USI1_USI>, <&clock VDOUT_CLK_PERIC0_USI1_USI>;
		clock-names = "gate_uart_clk1", "ipclk_uart1";
		interrupts = <GIC_SPI IRQ_USI1_USI_PERIC0 ITLH>;
		samsung,usi-phandle = <&sysreg_peric0>;
		samsung,usi-offset = <0x00000000>;
		reg = <0x00000000 0x10900000 0x00001000>;
		status = "disabled";
	};
	serial_2: serial@10910000 {
		compatible = "samsung,exynos-uart";
		samsung,fifo-size = <64>;
		reg-io-width = <4>;
		samsung,separate-uart-clk;
		samsung,usi-serial-v2;
		#address-cells = <0x00000001>;
		#size-cells = <0x00000000>;
		pinctrl-names = "default";
		pinctrl-0 = <&uart2_bus_single>; /* or _bus_dual */
		clocks = <&clock GATE_PERIC0_TOP0_USI2_USI>, <&clock VDOUT_CLK_PERIC0_USI2_USI>;
		clock-names = "gate_uart_clk2", "ipclk_uart2";
		interrupts = <GIC_SPI IRQ_USI2_USI_PERIC0 ITLH>;
		samsung,usi-phandle = <&sysreg_peric0>;
		samsung,usi-offset = <0x00000004>;
		reg = <0x00000000 0x10910000 0x00001000>;
		status = "disabled";
	};
	serial_3: serial@10920000 {
		compatible = "samsung,exynos-uart";
		samsung,fifo-size = <64>;
		reg-io-width = <4>;
		samsung,separate-uart-clk;
		samsung,usi-serial-v2;
		#address-cells = <0x00000001>;
		#size-cells = <0x00000000>;
		pinctrl-names = "default";
		pinctrl-0 = <&uart3_bus_single>; /* or _bus_dual */
		clocks = <&clock GATE_PERIC0_TOP0_USI3_USI>, <&clock VDOUT_CLK_PERIC0_USI3_USI>;
		clock-names = "gate_uart_clk3", "ipclk_uart3";
		interrupts = <GIC_SPI IRQ_USI3_USI_PERIC0 ITLH>;
		samsung,usi-phandle = <&sysreg_peric0>;
		samsung,usi-offset = <0x00000008>;
		reg = <0x00000000 0x10920000 0x00001000>;
		status = "disabled";
	};
	serial_4: serial@10930000 {
		compatible = "samsung,exynos-uart";
		samsung,fifo-size = <64>;
		reg-io-width = <4>;
		samsung,separate-uart-clk;
		samsung,usi-serial-v2;
		#address-cells = <0x00000001>;
		#size-cells = <0x00000000>;
		pinctrl-names = "default";
		pinctrl-0 = <&uart4_bus_single>; /* or _bus_dual */
		clocks = <&clock GATE_PERIC0_TOP0_USI4_USI>, <&clock VDOUT_CLK_PERIC0_USI4_USI>;
		clock-names = "gate_uart_clk4", "ipclk_uart4";
		interrupts = <GIC_SPI IRQ_USI4_USI_PERIC0 ITLH>;
		samsung,usi-phandle = <&sysreg_peric0>;
		samsung,usi-offset = <0x0000000c>;
		reg = <0x00000000 0x10930000 0x00001000>;
		status = "disabled";
	};
	serial_5: serial@10940000 {
		compatible = "samsung,exynos-uart";
		samsung,fifo-size = <64>;
		reg-io-width = <4>;
		samsung,separate-uart-clk;
		samsung,usi-serial-v2;
		#address-cells = <0x00000001>;
		#size-cells = <0x00000000>;
		pinctrl-names = "default";
		pinctrl-0 = <&uart5_bus_single>; /* or _bus_dual */
		clocks = <&clock GATE_PERIC0_TOP0_USI5_USI>, <&clock VDOUT_CLK_PERIC0_USI5_USI>;
		clock-names = "gate_uart_clk5", "ipclk_uart5";
		interrupts = <GIC_SPI IRQ_USI5_USI_PERIC0 ITLH>;
		samsung,usi-phandle = <&sysreg_peric0>;
		samsung,usi-offset = <0x00000010>;
		reg = <0x00000000 0x10940000 0x00001000>;
		status = "disabled";
	};
	serial_6: serial@10950000 {
		compatible = "samsung,exynos-uart";
		samsung,fifo-size = <64>;
		reg-io-width = <4>;
		samsung,separate-uart-clk;
		samsung,usi-serial-v2;
		#address-cells = <0x00000001>;
		#size-cells = <0x00000000>;
		pinctrl-names = "default";
		pinctrl-0 = <&uart6_bus_single>; /* or _bus_dual */
		clocks = <&clock GATE_PERIC0_TOP0_USI6_USI>, <&clock VDOUT_CLK_PERIC0_USI6_USI>;
		clock-names = "gate_uart_clk6", "ipclk_uart6";
		interrupts = <GIC_SPI IRQ_USI6_USI_PERIC0 ITLH>;
		samsung,usi-phandle = <&sysreg_peric0>;
		samsung,usi-offset = <0x00000014>;
		reg = <0x00000000 0x10950000 0x00001000>;
		status = "disabled";
	};
	serial_7: serial@10960000 {
		compatible = "samsung,exynos-uart";
		samsung,fifo-size = <64>;
		reg-io-width = <4>;
		samsung,separate-uart-clk;
		samsung,usi-serial-v2;
		#address-cells = <0x00000001>;
		#size-cells = <0x00000000>;
		pinctrl-names = "default";
		pinctrl-0 = <&uart7_bus_single>; /* or _bus_dual */
		clocks = <&clock GATE_PERIC0_TOP0_USI7_USI>, <&clock VDOUT_CLK_PERIC0_USI7_USI>;
		clock-names = "gate_uart_clk7", "ipclk_uart7";
		interrupts = <GIC_SPI IRQ_USI7_USI_PERIC0 ITLH>;
		samsung,usi-phandle = <&sysreg_peric0>;
		samsung,usi-offset = <0x00000018>;
		reg = <0x00000000 0x10960000 0x00001000>;
		status = "disabled";
	};
	serial_8: serial@10970000 {
		compatible = "samsung,exynos-uart";
		samsung,fifo-size = <64>;
		reg-io-width = <4>;
		samsung,separate-uart-clk;
		samsung,usi-serial-v2;
		#address-cells = <0x00000001>;
		#size-cells = <0x00000000>;
		pinctrl-names = "default";
		pinctrl-0 = <&uart8_bus_single>; /* or _bus_dual */
		clocks = <&clock GATE_PERIC0_TOP0_USI8_USI>, <&clock VDOUT_CLK_PERIC0_USI8_USI>;
		clock-names = "gate_uart_clk8", "ipclk_uart8";
		interrupts = <GIC_SPI IRQ_USI8_USI_PERIC0 ITLH>;
		samsung,usi-phandle = <&sysreg_peric0>;
		samsung,usi-offset = <0x0000001c>;
		reg = <0x00000000 0x10970000 0x00001000>;
		status = "disabled";
	};
	serial_14: serial@10A20000 {
		compatible = "samsung,exynos-uart";
		samsung,fifo-size = <64>;
		reg-io-width = <4>;
		samsung,separate-uart-clk;
		samsung,usi-serial-v2;
		#address-cells = <0x00000001>;
		#size-cells = <0x00000000>;
		pinctrl-names = "default";
		pinctrl-0 = <&uart14_bus_single>; /* or _bus_dual */
		clocks = <&clock GATE_PERIC0_TOP1_USI14_USI>, <&clock VDOUT_CLK_PERIC0_USI14_USI>;
		clock-names = "gate_uart_clk14", "ipclk_uart14";
		interrupts = <GIC_SPI IRQ_USI14_USI_PERIC0 ITLH>;
		samsung,usi-phandle = <&sysreg_peric0>;
		samsung,usi-offset = <0x00000028>;
		reg = <0x00000000 0x10a20000 0x00001000>;
		status = "disabled";
	};
	/* BLK_PERIC1 USI0_USI */
	serial_usi0: serial@10D10000 {
		compatible = "samsung,exynos-uart";
		samsung,fifo-size = <64>;
		reg-io-width = <4>;
		samsung,separate-uart-clk;
		samsung,usi-serial-v2;
		#address-cells = <0x00000001>;
		#size-cells = <0x00000000>;
		pinctrl-names = "default";
		pinctrl-0 = <&uart0_bus_single>; /* or _bus_dual */
		clocks = <&clock GATE_PERIC0_TOP1_USI0_UART>, <&clock VDOUT_CLK_PERIC0_USI0_UART>;
		clock-names = "gate_uart_clk15", "ipclk_uart15";
		interrupts = <GIC_SPI IRQ_USI0_USI_PERIC1 ITLH>;
		samsung,usi-phandle = <&sysreg_peric1>;
		samsung,usi-offset = <0x00000000>;
		reg = <0x00000000 0x10d10000 0x00001000>;
		status = "disabled";
	};
	serial_9: serial@10D20000 {
		compatible = "samsung,exynos-uart";
		samsung,fifo-size = <64>;
		reg-io-width = <4>;
		samsung,separate-uart-clk;
		samsung,usi-serial-v2;
		#address-cells = <0x00000001>;
		#size-cells = <0x00000000>;
		pinctrl-names = "default";
		pinctrl-0 = <&uart9_bus_single>; /* or _bus_dual */
		clocks = <&clock GATE_PERIC1_TOP0_USI9_USI>, <&clock VDOUT_CLK_PERIC1_USI9_USI>;
		clock-names = "gate_uart_clk9", "ipclk_uart9";
		interrupts = <GIC_SPI IRQ_USI9_USI_PERIC1 ITLH>;
		samsung,usi-phandle = <&sysreg_peric1>;
		samsung,usi-offset = <0x00000004>;
		reg = <0x00000000 0x10d20000 0x00001000>;
		status = "disabled";
	};
	serial_10: serial@10D30000 {
		compatible = "samsung,exynos-uart";
		samsung,fifo-size = <64>;
		reg-io-width = <4>;
		samsung,separate-uart-clk;
		samsung,usi-serial-v2;
		#address-cells = <0x00000001>;
		#size-cells = <0x00000000>;
		pinctrl-names = "default";
		pinctrl-0 = <&uart10_bus_single>; /* or _bus_dual */
		clocks = <&clock GATE_PERIC1_TOP0_USI10_USI>, <&clock VDOUT_CLK_PERIC1_USI10_USI>;
		clock-names = "gate_uart_clk10", "ipclk_uart10";
		interrupts = <GIC_SPI IRQ_USI10_USI_PERIC1 ITLH>;
		samsung,usi-phandle = <&sysreg_peric1>;
		samsung,usi-offset = <0x00000008>;
		reg = <0x00000000 0x10d30000 0x00001000>;
		status = "disabled";
	};
	serial_11: serial@10D40000 {
		compatible = "samsung,exynos-uart";
		samsung,fifo-size = <64>;
		reg-io-width = <4>;
		samsung,separate-uart-clk;
		samsung,usi-serial-v2;
		#address-cells = <0x00000001>;
		#size-cells = <0x00000000>;
		pinctrl-names = "default";
		pinctrl-0 = <&uart11_bus_single>; /* or _bus_dual */
		clocks = <&clock GATE_PERIC1_TOP0_USI11_USI>, <&clock VDOUT_CLK_PERIC1_USI11_USI>;
		clock-names = "gate_uart_clk11", "ipclk_uart11";
		interrupts = <GIC_SPI IRQ_USI11_USI_PERIC1 ITLH>;
		samsung,usi-phandle = <&sysreg_peric1>;
		samsung,usi-offset = <0x0000000c>;
		reg = <0x00000000 0x10d40000 0x00001000>;
		status = "disabled";
	};
	serial_12: serial@10D50000 {
		compatible = "samsung,exynos-uart";
		samsung,fifo-size = <64>;
		reg-io-width = <4>;
		samsung,separate-uart-clk;
		samsung,usi-serial-v2;
		#address-cells = <0x00000001>;
		#size-cells = <0x00000000>;
		pinctrl-names = "default";
		pinctrl-0 = <&uart12_bus_single>; /* or _bus_dual */
		clocks = <&clock GATE_PERIC1_TOP0_USI12_USI>, <&clock VDOUT_CLK_PERIC1_USI12_USI>;
		clock-names = "gate_uart_clk12", "ipclk_uart12";
		interrupts = <GIC_SPI IRQ_USI12_USI_PERIC1 ITLH>;
		samsung,usi-phandle = <&sysreg_peric1>;
		samsung,usi-offset = <0x00000010>;
		reg = <0x00000000 0x10d50000 0x00001000>;
		status = "disabled";
	};
	serial_13: serial@10D60000 {
		compatible = "samsung,exynos-uart";
		samsung,fifo-size = <64>;
		reg-io-width = <4>;
		samsung,separate-uart-clk;
		samsung,usi-serial-v2;
		#address-cells = <0x00000001>;
		#size-cells = <0x00000000>;
		pinctrl-names = "default";
		pinctrl-0 = <&uart13_bus_single>; /* or _bus_dual */
		clocks = <&clock GATE_PERIC1_TOP0_USI13_USI>, <&clock VDOUT_CLK_PERIC1_USI13_USI>;
		clock-names = "gate_uart_clk13", "ipclk_uart13";
		interrupts = <GIC_SPI IRQ_USI13_USI_PERIC1 ITLH>;
		samsung,usi-phandle = <&sysreg_peric1>;
		samsung,usi-offset = <0x00000014>;
		reg = <0x00000000 0x10d60000 0x00001000>;
		status = "disabled";
	};
	serial_15: serial@10DA0000 {
		compatible = "samsung,exynos-uart";
		samsung,fifo-size = <64>;
		reg-io-width = <4>;
		samsung,separate-uart-clk;
		samsung,usi-serial-v2;
		#address-cells = <0x00000001>;
		#size-cells = <0x00000000>;
		pinctrl-names = "default";
		pinctrl-0 = <&uart15_bus_single>; /* or _bus_dual */
		clocks = <&clock GATE_PERIC1_TOP0_USI15_USI>, <&clock VDOUT_CLK_PERIC1_USI15_USI>;
		clock-names = "gate_uart_clk15", "ipclk_uart15";
		interrupts = <GIC_SPI IRQ_USI15_USI_PERIC1 ITLH>;
		samsung,usi-phandle = <&sysreg_peric1>;
		samsung,usi-offset = <0x00000018>;
		reg = <0x00000000 0x10da0000 0x00001000>;
		status = "disabled";
	};
	serial_16: serial@10DB0000 {
		compatible = "samsung,exynos-uart";
		samsung,fifo-size = <64>;
		reg-io-width = <4>;
		samsung,separate-uart-clk;
		samsung,usi-serial-v2;
		#address-cells = <0x00000001>;
		#size-cells = <0x00000000>;
		pinctrl-names = "default";
		pinctrl-0 = <&uart16_bus_single>; /* or _bus_dual */
		clocks = <&clock GATE_PERIC1_TOP0_USI16_USI>, <&clock VDOUT_CLK_PERIC1_USI16_USI>;
		clock-names = "gate_uart_clk16", "ipclk_uart16";
		interrupts = <GIC_SPI IRQ_USI16_USI_PERIC1 ITLH>;
		samsung,usi-phandle = <&sysreg_peric1>;
		samsung,usi-offset = <0x0000001c>;
		reg = <0x00000000 0x10db0000 0x00001000>;
		status = "disabled";
	};
	/* BLK_ALIVE APM_USI0_UART */
	serial_17: serial@181A0000 {
		compatible = "samsung,exynos-uart";
		samsung,fifo-size = <256>;
		reg-io-width = <4>;
		samsung,separate-uart-clk;
		samsung,usi-serial-v2;
		#address-cells = <0x00000001>;
		#size-cells = <0x00000000>;
		pinctrl-names = "default";
		pinctrl-0 = <&uart17_bus>; /* or _bus_dual */
		clocks = <&clock MUX_APM_FUNC>, <&clock DOUT_CLK_APM_USI0_UART>;
		clock-names = "gate_uart_clk17", "ipclk_uart17";
		interrupts = <GIC_SPI IRQ_APM_USI0_UART_ALIVE ITLH>;
		samsung,usi-phandle = <&sysreg_apm>;
		samsung,usi-offset = <0x00000000>;
		reg = <0x00000000 0x181a0000 0x00001000>;
		status = "disabled";
	};
	/* BLK_ALIVE APM_USI1_UART */
	serial_18: serial@181B0000 {
		compatible = "samsung,exynos-uart";
		samsung,fifo-size = <256>;
		samsung,rts-trig-level = <0x01>;
		reg-io-width = <4>;
		samsung,separate-uart-clk;
		samsung,usi-serial-v2;
		samsung,rts-gpio-control;
		samsung,uart-logging;
		#address-cells = <0x00000001>;
		#size-cells = <0x00000000>;
		pinctrl-names = "default", "rts", "tx_dat";
		pinctrl-0 = <&uart18_bus>; /* or _bus_dual */
		pinctrl-1 = <&uart18_bus_rts &uart18_bus_tx_con>;
		pinctrl-2 = <&uart18_bus_tx_dat>;
		clocks = <&clock MUX_APM_FUNC>, <&clock DOUT_CLK_APM_USI1_UART>;
		clock-names = "gate_uart_clk18", "ipclk_uart18";
		interrupts = <GIC_SPI IRQ_APM_USI1_UART_ALIVE ITLH>;
		samsung,usi-phandle = <&sysreg_apm>;
		samsung,usi-offset = <0x00000004>;
		reg = <0x00000000 0x181b0000 0x00001000>;
		status = "disabled";
	};
	/* BLK_ALIVE APM_USI0_USI */
	serial_19: serial@181C0000 {
		compatible = "samsung,exynos-uart";
		samsung,fifo-size = <64>;
		reg-io-width = <4>;
		samsung,separate-uart-clk;
		samsung,usi-serial-v2;
		#address-cells = <0x00000001>;
		#size-cells = <0x00000000>;
		pinctrl-names = "default";
		pinctrl-0 = <&uart19_bus>; /* or _bus_dual */
		clocks = <&clock MUX_APM_FUNC>, <&clock DOUT_CLK_APM_USI0_USI>;
		clock-names = "gate_uart_clk19", "ipclk_uart19";
		interrupts = <GIC_SPI IRQ_APM_USI0_USI_ALIVE ITLH>;
		samsung,usi-phandle = <&sysreg_apm>;
		samsung,usi-offset = <0x00000008>;
		reg = <0x00000000 0x181c0000 0x00001000>;
		status = "disabled";
	};
	/* BLK_ALIVE APM_USI0_USI */
	spi_17: spi@181C0000 {
		compatible = "samsung,exynos-spi";
		samsung,spi-fifosize = <64>;
		swap-mode;
		#address-cells = <0x00000001>;
		#size-cells = <0x00000000>;
		dma-names = "tx", "rx";
		clocks = <&clock MUX_APM_FUNC>, <&clock DOUT_CLK_APM_USI0_USI>;
		clock-names = "ipclk_spi", "gate_spi_clk";
		interrupts = <GIC_SPI IRQ_APM_USI0_USI_ALIVE ITLH>;
		samsung,usi-phandle = <&sysreg_apm>;
		samsung,usi-offset = <0x00000008>;
		reg = <0x00000000 0x181c0000 0x00001000>;
		status = "disabled";
	};
};
